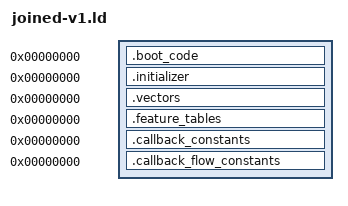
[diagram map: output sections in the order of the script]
OUTPUT_ARCH(riscv)
SECTIONS
{
 .boot_code 0 : SUBALIGN(2) { *(.boot_code)
  *(.text.tsl9_callback_flow_external_171ba)
  *(.text.tsl9_rom_driver_block_171cc)
  *(.text.tsl9_rom_driver_entry_171de)
  *(.text.tsl9_rom_driver_block_171ea)
  *(.text.tsl9_rom_driver_block_171ec)
  *(.text.tsl9_rom_driver_block_171fe)
  *(.text.tsl9_rom_driver_block_1720c)
  *(.text.tsl9_rom_driver_block_1720e)
  *(.text.tsl9_rom_driver_block_17216)
  *(.text.tsl9_rom_driver_block_1721c)
  *(.text.tsl9_rom_driver_block_17228)
  *(.text.tsl9_rom_driver_block_17232)
  *(.text.tsl9_rom_driver_block_17234)
  *(.text.tsl9_rom_driver_block_17252)
  *(.text.tsl9_rom_driver_block_1726a)
  *(.text.tsl9_rom_driver_block_1726e)
  *(.text.tsl9_rom_driver_block_17270)
  *(.text.tsl9_rom_driver_block_1727a)
  *(.text.tsl9_rom_driver_block_1727e)
  *(.text.tsl9_rom_driver_block_17280)
  *(.text.tsl9_rom_driver_block_1728a)
  *(.text.tsl9_rom_driver_block_17290)
  *(.text.tsl9_rom_driver_block_172a0)
  *(.text.tsl9_rom_driver_entry_172b6)
  *(.text.tsl9_rom_driver_block_172c6)
  *(.text.tsl9_rom_driver_block_172ca)
  *(.text.tsl9_rom_driver_block_172e2)
  *(.text.tsl9_rom_driver_block_172e6)
  *(.text.tsl9_rom_driver_block_172ec)
  *(.text.tsl9_rom_driver_block_172f4)
  *(.text.tsl9_rom_driver_block_172f6)
  *(.text.tsl9_rom_driver_block_172fa)
  *(.text.tsl9_rom_driver_block_17300)
  *(.text.tsl9_rom_driver_block_17304)
  *(.text.tsl9_rom_driver_block_1730e)
  *(.text.tsl9_rom_driver_block_17316)
  *(.text.tsl9_rom_driver_block_1731a)
  *(.text.tsl9_rom_driver_entry_17320)
  *(.text.tsl9_rom_driver_block_17328)
  *(.text.tsl9_rom_driver_block_1732a)
  *(.text.tsl9_rom_driver_block_1733e)
  *(.text.tsl9_rom_driver_entry_17344)
  *(.text.tsl9_rom_driver_block_17352)
  *(.text.tsl9_rom_driver_block_1735a)
  *(.text.tsl9_rom_driver_block_1735c)
  *(.text.tsl9_rom_driver_block_17362)
  *(.text.tsl9_rom_driver_block_17364)
  *(.text.tsl9_rom_driver_block_17372)
  *(.text.tsl9_rom_driver_block_17384)
  *(.text.tsl9_rom_driver_block_17392)
  *(.text.tsl9_rom_driver_block_17396)
  *(.text.tsl9_rom_driver_block_17398)
  *(.text.tsl9_main_provider_173a2)
  *(.text.tsl9_rom_driver_block_173b8)
  *(.text.tsl9_rom_driver_block_173c6)
  *(.text.tsl9_rom_driver_block_173d8)
  *(.text.tsl9_rom_driver_block_173e6)
 }
 .initializer 0 : SUBALIGN(4) { *(.initializer) }
 .vectors 0 : SUBALIGN(4) { *(.vectors) }
 .feature_tables 0 : SUBALIGN(4) { *(.feature_tables) }
 .callback_constants 0 : SUBALIGN(4) { *(.callback_constants) }
 .callback_flow_constants 0 : SUBALIGN(4) { *(.callback_flow_constants) }
 /DISCARD/ : { *(.comment) *(.riscv.attributes) *(.llvm_addrsig) }
}
